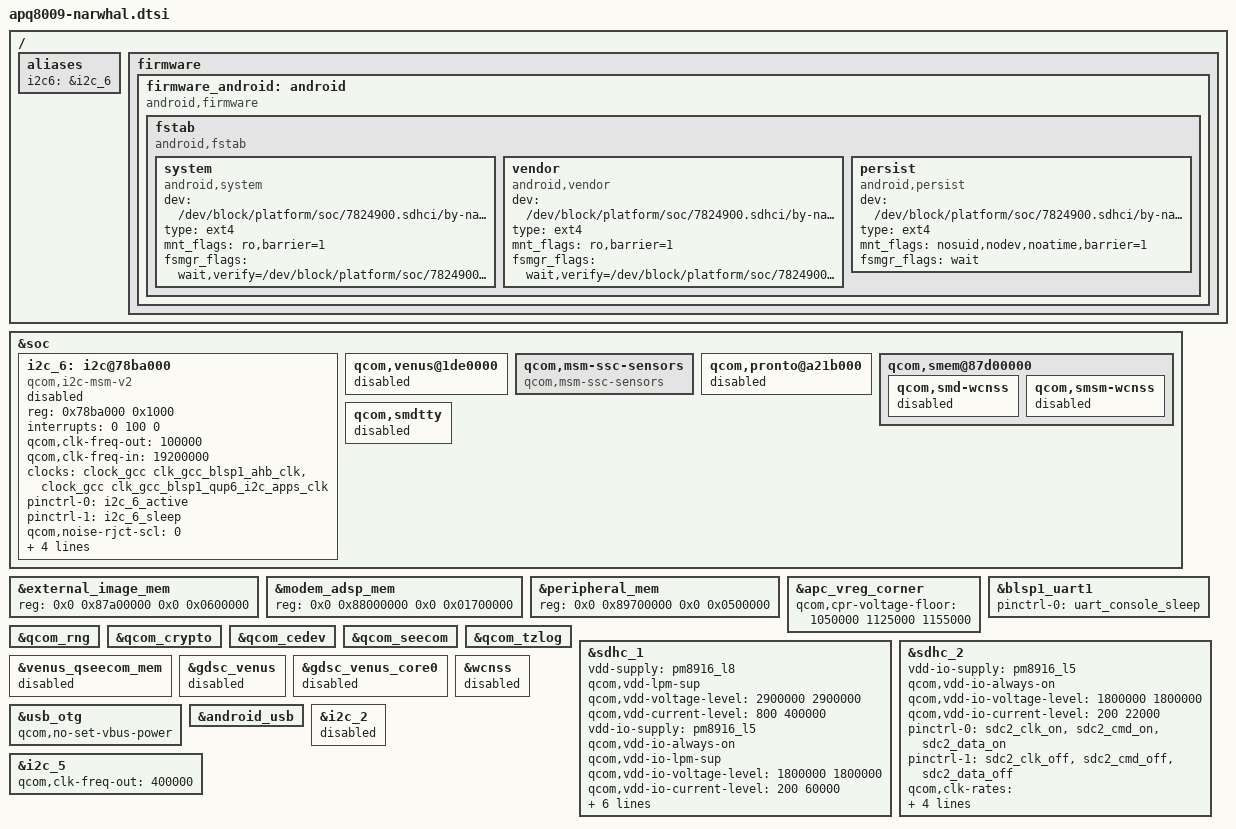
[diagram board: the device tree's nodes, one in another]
/* Copyright (c) 2017, LGE Inc. All rights reserved.
 *
 * This program is free software; you can redistribute it and/or modify
 * it under the terms of the GNU General Public License version 2 and
 * only version 2 as published by the Free Software Foundation.
 *
 * This program is distributed in the hope that it will be useful,
 * but WITHOUT ANY WARRANTY; without even the implied warranty of
 * MERCHANTABILITY or FITNESS FOR A PARTICULAR PURPOSE.  See the
 * GNU General Public License for more details.
 */

#include "../qcom/msm8909.dtsi"
#include "../qcom/msm8909w-gpu.dtsi"
#include "../qcom/msm8909-pm8916.dtsi"
#include "../qcom/msm8909w.dtsi"
#include "apq8009-narwhal-pinctrl.dtsi"
#include "apq8009-narwhal-pm.dtsi"
#include "apq8009-pm8916-narwhal.dtsi"
#include "apq8009-narwhal-input.dtsi"
#include "apq8009-narwhal-panel.dtsi"
#include "apq8009-narwhal-sound.dtsi"
#include "apq8009-narwhal-misc.dtsi"
#include "apq8009-narwhal-connectivity.dtsi"
#include "apq8009-narwhal-paj9124u1.dtsi"

&soc {
	i2c_6: i2c@78ba000 { /* BLSP1 QUP6 */
		status = "disabled";
		compatible = "qcom,i2c-msm-v2";
		#address-cells = <1>;
		#size-cells = <0>;
		reg-names = "qup_phys_addr";
		reg = <0x78ba000 0x1000>;
		interrupt-names = "qup_irq";
		interrupts = <0 100 0>;
		qcom,clk-freq-out = <100000>; //100Khz
		qcom,clk-freq-in  = <19200000>;
		clock-names = "iface_clk", "core_clk";
		clocks = <&clock_gcc clk_gcc_blsp1_ahb_clk>,
			<&clock_gcc clk_gcc_blsp1_qup6_i2c_apps_clk>;

		pinctrl-names = "i2c_active", "i2c_sleep";
		pinctrl-0 = <&i2c_6_active>;
		pinctrl-1 = <&i2c_6_sleep>;
		qcom,noise-rjct-scl = <0>;
		qcom,noise-rjct-sda = <0>;
		dmas = <&dma_blsp1 14 64 0x20000020 0x20>,
			<&dma_blsp1 15 32 0x20000020 0x20>;
		dma-names = "tx", "rx";
		qcom,master-id = <86>;
	};
};

/{
	aliases {
		/delete-property/i2c1;
		/delete-property/i2c3;
		i2c6 = &i2c_6; /* I2C6 controller device */
	};

	firmware {
		firmware_android: android {};
	};
};

#include "apq8009-narwhal-movement.dtsi"

&external_image_mem {
	reg = <0x0 0x87a00000 0x0 0x0600000>;
};

&modem_adsp_mem {
	reg = <0x0 0x88000000 0x0 0x01700000>;
};

&peripheral_mem {
	reg = <0x0 0x89700000 0x0 0x0500000>;
};

&soc {
	/delete-node/ i2c@78b5000; /* i2c_1 */
	/delete-node/ i2c@78b7000; /* i2c_3 */

	qcom,venus@1de0000 {
		status = "disabled";
	};

	qcom,msm-ssc-sensors {
		compatible = "qcom,msm-ssc-sensors";
	};

	qcom,pronto@a21b000 {
		status = "disabled";
	};

	qcom,smem@87d00000 {
		qcom,smd-wcnss {
			status = "disabled";
		};
		qcom,smsm-wcnss {
			status = "disabled";
		};
	};

	qcom,smdtty {
		status = "disabled";
	};
};

&apc_vreg_corner {
	qcom,cpr-voltage-floor = <1050000 1125000 1155000>;
};

&blsp1_uart1 {
	status = "ok";
	pinctrl-names = "default";
	pinctrl-0 = <&uart_console_sleep>;
};

&qcom_rng {
	status = "okay";
};

&qcom_crypto {
	status = "okay";
};

&qcom_cedev {
	status = "okay";
};

&qcom_seecom {
	status = "okay";
};

&qcom_tzlog {
	status = "okay";
};

&sdhc_1 {
	vdd-supply = <&pm8916_l8>;
	qcom,vdd-lpm-sup;
	qcom,vdd-voltage-level = <2900000 2900000>;
	qcom,vdd-current-level = <800 400000>;

	vdd-io-supply = <&pm8916_l5>;
	qcom,vdd-io-always-on;
	qcom,vdd-io-lpm-sup;
	qcom,vdd-io-voltage-level = <1800000 1800000>;
	qcom,vdd-io-current-level = <200 60000>;

	pinctrl-names = "active", "sleep";
	pinctrl-0 = <&sdc1_clk_on &sdc1_cmd_on &sdc1_data_on>;
	pinctrl-1 = <&sdc1_clk_off &sdc1_cmd_off &sdc1_data_off>;

	qcom,bus-speed-mode = "HS200_1p8v", "DDR_1p8v";
	qcom,nonremovable;

	status = "ok";
};

&sdhc_2 {
	/delete-property/vdd-supply;
	vdd-io-supply = <&pm8916_l5>;
	qcom,vdd-io-always-on;
	qcom,vdd-io-voltage-level = <1800000 1800000>;
	qcom,vdd-io-current-level = <200 22000>;

	pinctrl-names = "active", "sleep";
	pinctrl-0 = <&sdc2_clk_on &sdc2_cmd_on &sdc2_data_on>;
	pinctrl-1 = <&sdc2_clk_off &sdc2_cmd_off &sdc2_data_off>;

	qcom,clk-rates = <400000 20000000 25000000 50000000>;

	qcom,bus-width = <4>;
	qcom,nonremovable;
	qcom,core_3_0v_support = <1>;
	status = "ok";
};

&venus_qseecom_mem {
	status = "disabled";
};

&gdsc_venus {
	status = "disabled";
};

&gdsc_venus_core0 {
	status = "disabled";
};

&wcnss {
	status = "disabled";
};

&usb_otg {
	qcom,no-set-vbus-power;
};

&android_usb {
	/delete-property/qcom,pm-qos-latency;
};

&i2c_2 {
	status = "disabled";
};

&i2c_5 {
	qcom,clk-freq-out = <400000>;
};

&firmware_android {
	compatible = "android,firmware";
	fstab {
		compatible = "android,fstab";
		system {
			compatible = "android,system";
			dev = "/dev/block/platform/soc/7824900.sdhci/by-name/system";
			type = "ext4";
			mnt_flags = "ro,barrier=1";
			fsmgr_flags = "wait,verify=/dev/block/platform/soc/7824900.sdhci/by-name/misc";
		};
		vendor {
			compatible = "android,vendor";
			dev = "/dev/block/platform/soc/7824900.sdhci/by-name/vendor";
			type = "ext4";
			mnt_flags = "ro,barrier=1";
			fsmgr_flags = "wait,verify=/dev/block/platform/soc/7824900.sdhci/by-name/misc";
		};
		persist {
			compatible = "android,persist";
			dev = "/dev/block/platform/soc/7824900.sdhci/by-name/persist";
			type = "ext4";
			mnt_flags = "nosuid,nodev,noatime,barrier=1";
			fsmgr_flags = "wait";
		};
	};
};
